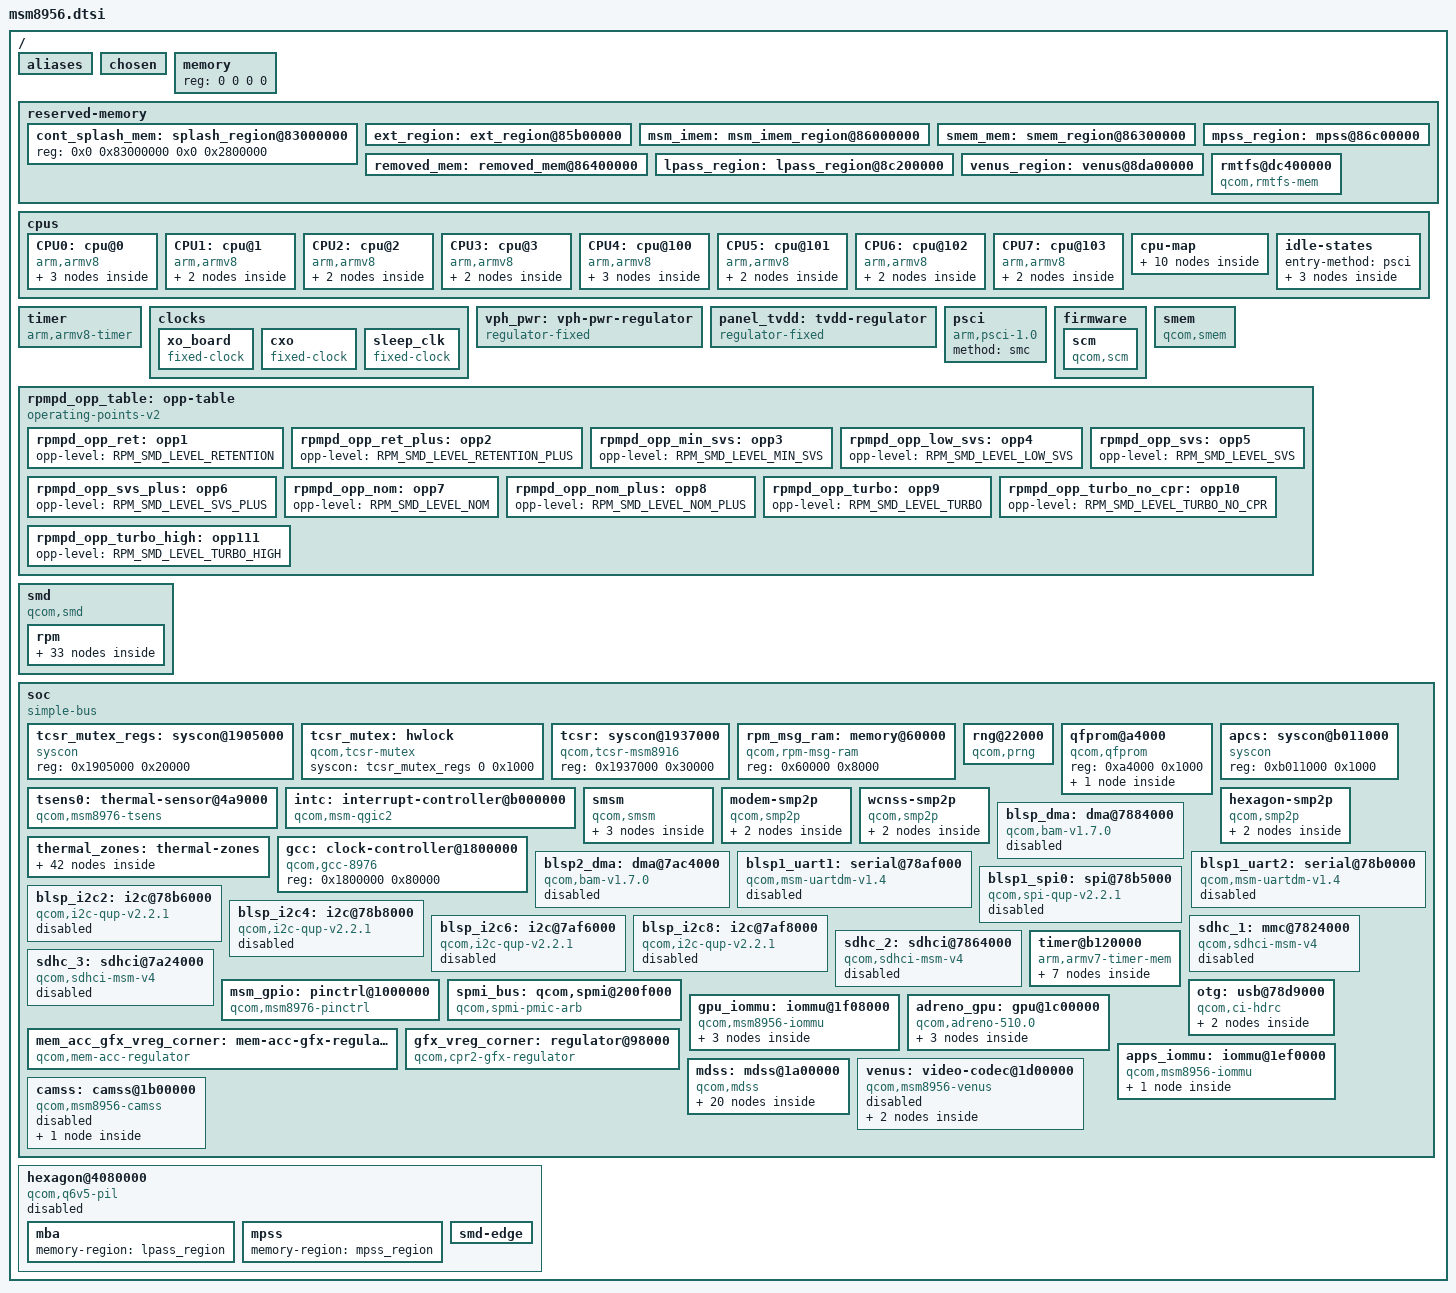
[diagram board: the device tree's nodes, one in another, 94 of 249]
// SPDX-License-Identifier: GPL-2.0
/* Copyright (c) 2014-2015, The Linux Foundation. All rights reserved.
 * Copyright (c) 2016-2019 AngeloGioacchino Del Regno <kholk11@gmail.com>
 */

#include <dt-bindings/interrupt-controller/arm-gic.h>
#include <dt-bindings/clock/qcom,gcc-msm8976.h>
#include <dt-bindings/clock/qcom,rpmcc.h>
#include <dt-bindings/power/qcom-rpmpd.h>

/ {
	interrupt-parent = <&intc>;

	qcom,msm-id = <266 0x10001>;

	#address-cells = <2>;
	#size-cells = <2>;

	aliases {
		sdhc1 = &sdhc_1; /* SDC1 eMMC slot */
		sdhc2 = &sdhc_2; /* SDC2 SD card slot */
		sdhc3 = &sdhc_3; /* SDC3 SDIO card slot */
		i2c2  = &blsp_i2c2;
		i2c4  = &blsp_i2c4;
		i2c6  = &blsp_i2c6;
		i2c8  = &blsp_i2c8;
		spi0  = &blsp1_spi0;
	};

	chosen { };

	memory {
		device_type = "memory";
		/* We expect the bootloader to fill in the reg */
		reg = <0 0 0 0>;
	};

	reserved-memory {
		#address-cells = <2>;
		#size-cells = <2>;
		ranges;

		cont_splash_mem: splash_region@83000000 {
			reg = <0x0 0x83000000 0x0 0x2800000>;
		};

		ext_region: ext_region@85b00000 {
			reg = <0x0 0x85b00000 0x0 0x500000>;
			no-map;
		};

		msm_imem: msm_imem_region@86000000 {
			reg = <0x0 0x86000000 0x0 0x300000>;
			no-map;
		};

		smem_mem: smem_region@86300000 {
			reg = <0x0 0x86300000 0x0 0x100000>;
			no-map;
		};

		removed_mem: removed_mem@86400000 {
			reg = <0x0 0x86400000 0x0 0x800000>;
			no-map;
		};

		mpss_region: mpss@86c00000 {
			reg = <0x0 0x86c00000 0x0 0x5600000>;
			no-map;
		};

		lpass_region: lpass_region@8c200000 {
			reg = <0x0 0x8c200000 0x0 0x1800000>;
			no-map;
		};

		venus_region: venus@8da00000 {
			reg = <0x0 0x8DA00000 0x0 0x2600000>;
			no-map;
		};
/*
		tz_apps: tz_apps@8dd00000 {
			reg = <0x0 0x8dd00000 0x0 0x1400000>;
			no-map;
		};
*/
		rmtfs@dc400000 {
			compatible = "qcom,rmtfs-mem";

			size = <0x0 0x200000>;
			alloc-ranges = <0x0 0xdc400000 0x0 0x2000000>;
			no-map;

			qcom,client-id = <1>;
		};
	};

	cpus {
		#address-cells = <1>;
		#size-cells = <0>;

		CPU0: cpu@0 {
			device_type = "cpu";
			compatible = "arm,armv8";
			reg = <0x0>;
			enable-method = "psci";
			cpu-idle-states = <&LITTLE_CPU_SLEEP_0>;
			capacity-dmips-mhz = <1024>;
			next-level-cache = <&L2_0>;
			#cooling-cells = <2>;
			L2_0: l2-cache {
				compatible = "arm,arch-cache";
				cache-level = <2>;
			};
			L1_I_0: l1-icache {
				compatible = "arm,arch-cache";
			};
			L1_D_0: l1-dcache {
				compatible = "arm,arch-cache";
			};
		};

		CPU1: cpu@1 {
			device_type = "cpu";
			compatible = "arm,armv8";
			reg = <0x1>;
			enable-method = "psci";
			cpu-idle-states = <&LITTLE_CPU_SLEEP_0>;
			capacity-dmips-mhz = <1024>;
			next-level-cache = <&L2_0>;
			#cooling-cells = <2>;
			L1_I_1: l1-icache {
				compatible = "arm,arch-cache";
			};
			L1_D_1: l1-dcache {
				compatible = "arm,arch-cache";
			};
		};

		CPU2: cpu@2 {
			device_type = "cpu";
			compatible = "arm,armv8";
			reg = <0x2>;
			enable-method = "psci";
			cpu-idle-states = <&LITTLE_CPU_SLEEP_0>;
			capacity-dmips-mhz = <1024>;
			next-level-cache = <&L2_0>;
			#cooling-cells = <2>;
			L1_I_2: l1-icache {
				compatible = "arm,arch-cache";
			};
			L1_D_2: l1-dcache {
				compatible = "arm,arch-cache";
			};
		};

		CPU3: cpu@3 {
			device_type = "cpu";
			compatible = "arm,armv8";
			reg = <0x3>;
			enable-method = "psci";
			cpu-idle-states = <&LITTLE_CPU_SLEEP_0>;
			capacity-dmips-mhz = <1024>;
			next-level-cache = <&L2_0>;
			#cooling-cells = <2>;
			L1_I_3: l1-icache {
				compatible = "arm,arch-cache";
			};
			L1_D_3: l1-dcache {
				compatible = "arm,arch-cache";
			};
		};

		CPU4: cpu@100 {
			device_type = "cpu";
			compatible = "arm,armv8";
			reg = <0x100>;
			enable-method = "psci";
			cpu-idle-states = <&BIG_CPU_SLEEP_0 &BIG_CPU_SLEEP_1>;
			capacity-dmips-mhz = <1830>;
			next-level-cache = <&L2_1>;
			#cooling-cells = <2>;
			L2_1: l2-cache {
				compatible = "arm,arch-cache";
				cache-level = <2>;
			};
			L1_I_100: l1-icache {
				compatible = "arm,arch-cache";
			};
			L1_D_100: l1-dcache {
				compatible = "arm,arch-cache";
			};
		};

		CPU5: cpu@101 {
			device_type = "cpu";
			compatible = "arm,armv8";
			reg = <0x101>;
			enable-method = "psci";
			cpu-idle-states = <&BIG_CPU_SLEEP_0 &BIG_CPU_SLEEP_1>;
			capacity-dmips-mhz = <1830>;
			next-level-cache = <&L2_1>;
			#cooling-cells = <2>;
			L1_I_101: l1-icache {
				compatible = "arm,arch-cache";
			};
			L1_D_101: l1-dcache {
				compatible = "arm,arch-cache";
			};
		};

		CPU6: cpu@102 {
			device_type = "cpu";
			compatible = "arm,armv8";
			reg = <0x102>;
			enable-method = "psci";
			cpu-idle-states = <&BIG_CPU_SLEEP_0 &BIG_CPU_SLEEP_1>;
			capacity-dmips-mhz = <1830>;
			next-level-cache = <&L2_1>;
			#cooling-cells = <2>;
			L1_I_102: l1-icache {
				compatible = "arm,arch-cache";
			};
			L1_D_102: l1-dcache {
				compatible = "arm,arch-cache";
			};
		};

		CPU7: cpu@103 {
			device_type = "cpu";
			compatible = "arm,armv8";
			reg = <0x103>;
			enable-method = "psci";
			cpu-idle-states = <&BIG_CPU_SLEEP_0 &BIG_CPU_SLEEP_1>;
			capacity-dmips-mhz = <1830>;
			next-level-cache = <&L2_1>;
			#cooling-cells = <2>;
			L1_I_103: l1-icache {
				compatible = "arm,arch-cache";
			};
			L1_D_103: l1-dcache {
				compatible = "arm,arch-cache";
			};
		};

		cpu-map {
			cluster0 {
				core0 {
					cpu = <&CPU0>;
				};

				core1 {
					cpu = <&CPU1>;
				};

				core2 {
					cpu = <&CPU2>;
				};

				core3 {
					cpu = <&CPU3>;
				};
			};

			cluster1 {
				core0 {
					cpu = <&CPU4>;
				};

				core1 {
					cpu = <&CPU5>;
				};

				core2 {
					cpu = <&CPU6>;
				};

				core3 {
					cpu = <&CPU7>;
				};
			};
		};

		idle-states {
			entry-method = "psci";

			LITTLE_CPU_SLEEP_0: cpu-sleep-0-0 {
				compatible = "arm,idle-state";
				idle-state-name = "little-power-collapse";
				arm,psci-suspend-param = <0x40000003>;
				entry-latency-us = <181>;
				exit-latency-us = <149>;
				min-residency-us = <703>;
				local-timer-stop;
			};

			BIG_CPU_SLEEP_0: cpu-sleep-1-0 {
				compatible = "arm,idle-state";
				idle-state-name = "big-retention";
				arm,psci-suspend-param = <0x00000002>;
				entry-latency-us = <142>;
				exit-latency-us = <99>;
				min-residency-us = <242>;
			};

			BIG_CPU_SLEEP_1: cpu-sleep-1-1 {
				compatible = "arm,idle-state";
				idle-state-name = "big-power-collapse";
				arm,psci-suspend-param = <0x40000003>;
				entry-latency-us = <158>;
				exit-latency-us = <144>;
				min-residency-us = <863>;
				local-timer-stop;
			};
		};
	};

	timer {
		compatible = "arm,armv8-timer";
		interrupts = <GIC_PPI 2 (GIC_CPU_MASK_SIMPLE(1) | IRQ_TYPE_LEVEL_LOW)>,
			     <GIC_PPI 3 (GIC_CPU_MASK_SIMPLE(1) | IRQ_TYPE_LEVEL_LOW)>,
			     <GIC_PPI 4 (GIC_CPU_MASK_SIMPLE(1) | IRQ_TYPE_LEVEL_LOW)>,
			     <GIC_PPI 1 (GIC_CPU_MASK_SIMPLE(1) | IRQ_TYPE_LEVEL_LOW)>;
		clock-frequency = <19200000>;
	};

	clocks {
		xo_board: xo_board {
			compatible = "fixed-clock";
			#clock-cells = <0>;
			clock-frequency = <19200000>;
			clock-output-names = "xo_board";
		};

		cxo: cxo {
			compatible = "fixed-clock";
			#clock-cells = <0>;
			clock-frequency = <19200000>;
			clock-output-names = "cxo";
		};

		sleep_clk: sleep_clk {
			compatible = "fixed-clock";
			#clock-cells = <0>;
			clock-frequency = <32764>;
			clock-output-names = "sleep_clk";
		};
	};

	vph_pwr: vph-pwr-regulator {
		compatible = "regulator-fixed";
		regulator-name = "vph_pwr";
		regulator-always-on;
		regulator-boot-on;
	};

	panel_tvdd: tvdd-regulator {
		compatible = "regulator-fixed";
		regulator-name = "panel-tvdd";
		gpio = <&msm_gpio 126 0>;
		// This regulator is active-low.
	};

	psci {
		compatible = "arm,psci-1.0";
		method = "smc";
	};

	firmware {
		scm: scm {
			compatible = "qcom,scm";
			clocks = <&gcc GCC_CRYPTO_CLK>,
				 <&gcc GCC_CRYPTO_AXI_CLK>,
				 <&gcc GCC_CRYPTO_AHB_CLK>;
			clock-names = "core", "bus", "iface";
			#reset-cells = <1>;

			qcom,dload-mode = <&tcsr 0x6100>;
		};
	};

	smem {
		compatible = "qcom,smem";

		memory-region = <&smem_mem>;
		qcom,rpm-msg-ram = <&rpm_msg_ram>;

		hwlocks = <&tcsr_mutex 3>;
	};

	rpmpd_opp_table: opp-table {
		compatible = "operating-points-v2";

		rpmpd_opp_ret: opp1 {
			opp-level = <RPM_SMD_LEVEL_RETENTION>;
		};

		rpmpd_opp_ret_plus: opp2 {
			opp-level = <RPM_SMD_LEVEL_RETENTION_PLUS>;
		};

		rpmpd_opp_min_svs: opp3 {
			opp-level = <RPM_SMD_LEVEL_MIN_SVS>;
		};

		rpmpd_opp_low_svs: opp4 {
			opp-level = <RPM_SMD_LEVEL_LOW_SVS>;
		};

		rpmpd_opp_svs: opp5 {
			opp-level = <RPM_SMD_LEVEL_SVS>;
		};

		rpmpd_opp_svs_plus: opp6 {
			opp-level = <RPM_SMD_LEVEL_SVS_PLUS>;
		};

		rpmpd_opp_nom: opp7 {
			opp-level = <RPM_SMD_LEVEL_NOM>;
		};

		rpmpd_opp_nom_plus: opp8 {
			opp-level = <RPM_SMD_LEVEL_NOM_PLUS>;
		};

		rpmpd_opp_turbo: opp9 {
			opp-level = <RPM_SMD_LEVEL_TURBO>;
		};

		rpmpd_opp_turbo_no_cpr: opp10 {
			opp-level = <RPM_SMD_LEVEL_TURBO_NO_CPR>;
		};

		rpmpd_opp_turbo_high: opp111 {
			opp-level = <RPM_SMD_LEVEL_TURBO_HIGH>;
		};
	};

	smd {
		compatible = "qcom,smd";

		rpm {
			interrupts = <GIC_SPI 168 IRQ_TYPE_EDGE_RISING>;
			qcom,ipc = <&apcs 8 0>;
			qcom,smd-edge = <15>;

			rpm_requests {
				compatible = "qcom,rpm-msm8976";
				qcom,smd-channels = "rpm_requests";

				rpmcc: qcom,rpmcc {
					compatible = "qcom,rpmcc-msm8976";
					#clock-cells = <1>;
				};

				rpmpd: power-controller {
					compatible = "qcom,msm8956-rpmpd";
					#power-domain-cells = <1>;
					operating-points-v2 = <&rpmpd_opp_table>;
				};

				smd_rpm_regulators: pm8956-regulators {
					compatible = "qcom,rpm-pm8950-regulators";

					pm8950_s1: s1 {};
					pm8950_s2: s2 {};
					pm8950_s3: s3 {};
					pm8950_s4: s4 {};
					pm8950_s5: s5 {};
					pm8950_s6: s6 {};

					pm8950_l1: l1 {};
					pm8950_l2: l2 {};
					pm8950_l3: l3 {};
					pm8950_l4: l4 {};
					pm8950_l5: l5 {};
					pm8950_l6: l6 {};
					pm8950_l7: l7 {};
					pm8950_l8: l8 {};
					pm8950_l9: l9 {};
					pm8950_l10: l10 {};
					pm8950_l11: l11 {};
					pm8950_l12: l12 {};
					pm8950_l13: l13 {};
					pm8950_l14: l14 {};
					pm8950_l15: l15 {};
					pm8950_l16: l16 {};
					pm8950_l17: l17 {};
					pm8950_l18: l18 {};
					pm8950_l19: l19 {};
					pm8950_l20: l20 {};
					pm8950_l21: l21 {};
					pm8950_l22: l22 {};
					pm8950_l23: l23 {};
				};
			};
		};
	};

	soc: soc {
		#address-cells = <1>;
		#size-cells = <1>;
		ranges = <0 0 0 0xffffffff>;
		compatible = "simple-bus";

		tcsr_mutex_regs: syscon@1905000 {
			compatible = "syscon";
			reg = <0x1905000 0x20000>;
		};

		tcsr_mutex: hwlock {
			compatible = "qcom,tcsr-mutex";
			syscon = <&tcsr_mutex_regs 0 0x1000>;
			#hwlock-cells = <1>;
		};

		tcsr: syscon@1937000 {
			compatible = "qcom,tcsr-msm8916", "syscon";
			reg = <0x1937000 0x30000>;
		};

		rpm_msg_ram: memory@60000 {
			compatible = "qcom,rpm-msg-ram";
			reg = <0x60000 0x8000>;
		};

		rng@22000 {
			compatible = "qcom,prng";
			reg = <0x22000 0x140>;
			clocks = <&gcc GCC_PRNG_AHB_CLK>;
			clock-names = "core";
		};

		qfprom@a4000 {
			compatible = "qcom,qfprom";
			reg = <0xa4000 0x1000>;
			#address-cells = <1>;
			#size-cells = <1>;

			tsens_caldata: caldata@218 {
				reg = <0x218 0x18>;
			};
		};

		tsens0: thermal-sensor@4a9000 {
			compatible = "qcom,msm8976-tsens";
			reg = <0x4a9000 0x1000>, /* TM */
			      <0x4a8000 0x1000>; /* SROT */
			nvmem-cells = <&tsens_caldata>;
			nvmem-cell-names = "calib";
			#qcom,sensors = <11>;
			#thermal-sensor-cells = <1>;
		};

		intc: interrupt-controller@b000000 {
			compatible = "qcom,msm-qgic2";
			interrupt-controller;
			#interrupt-cells = <3>;
			reg = <0x0b000000 0x1000>,
			      <0x0b002000 0x1000>;
		};

		/* TODO: PLLs! A53PLL: 0xb016000 HFPLL: 0xb116000 */

		apcs: syscon@b011000 {
			compatible = "syscon";
			reg = <0xb011000 0x1000>;
		};

		smsm {
			compatible = "qcom,smsm";

			#address-cells = <1>;
			#size-cells = <0>;

			qcom,ipc-1 = <&apcs 8 12>;
			qcom,ipc-2 = <&apcs 8 9>;
			qcom,ipc-3 = <&apcs 8 18>;

			apps_smsm: apps@0 {
				reg = <0>;
				#qcom,smem-state-cells = <1>;
			};

			hexagon_smsm: hexagon@1 {
				reg = <1>;
				interrupts = <0 290 IRQ_TYPE_EDGE_RISING>;

				interrupt-controller;
				#interrupt-cells = <2>;
			};

			wcnss_smsm: wcnss@6 {
				reg = <6>;
				interrupts = <GIC_SPI 144 IRQ_TYPE_EDGE_RISING>;

				interrupt-controller;
				#interrupt-cells = <2>;
			};
		};

		modem-smp2p {
			compatible = "qcom,smp2p";
			qcom,smem = <435>, <428>;

			interrupts = <GIC_SPI 27 IRQ_TYPE_EDGE_RISING>;

			qcom,ipc = <&apcs 8 13>;

			qcom,local-pid = <0>;
			qcom,remote-pid = <1>;

			modem_smp2p_out: master-kernel {
				qcom,entry-name = "master-kernel";

				#qcom,smem-state-cells = <1>;
			};

			modem_smp2p_in: slave-kernel {
				qcom,entry-name = "slave-kernel";

				interrupt-controller;
				#interrupt-cells = <2>;
			};
		};

		wcnss-smp2p {
			compatible = "qcom,smp2p";
			qcom,smem = <451>, <431>;

			interrupts = <GIC_SPI 143 IRQ_TYPE_EDGE_RISING>;

			qcom,ipc = <&apcs 8 17>;

			qcom,local-pid = <0>;
			qcom,remote-pid = <4>;

			wcnss_smp2p_out: master-kernel {
				qcom,entry-name = "master-kernel";

				#qcom,smem-state-cells = <1>;
			};

			wcnss_smp2p_in: slave-kernel {
				qcom,entry-name = "slave-kernel";

				interrupt-controller;
				#interrupt-cells = <2>;
			};
		};

		hexagon-smp2p {
			compatible = "qcom,smp2p";
			qcom,smem = <443>, <429>;

			interrupts = <GIC_SPI 291 IRQ_TYPE_EDGE_RISING>;

			qcom,ipc = <&apcs 8 10>;

			qcom,local-pid = <0>;
			qcom,remote-pid = <2>;

			adsp_smp2p_out: master-kernel {
				qcom,entry-name = "master-kernel";

				#qcom,smem-state-cells = <1>;
			};

			adsp_smp2p_in: slave-kernel {
				qcom,entry-name = "slave-kernel";

				interrupt-controller;
				#interrupt-cells = <2>;
			};
		};

		thermal_zones: thermal-zones {};

		gcc: clock-controller@1800000 {
			compatible = "qcom,gcc-8976";
			#clock-cells = <1>;
			#reset-cells = <1>;
			#power-domain-cells = <1>;
			reg = <0x1800000 0x80000>;
		};

		blsp_dma: dma@7884000 {
			compatible = "qcom,bam-v1.7.0";
			reg = <0x07884000 0x1f000>;
			interrupts = <GIC_SPI 238 IRQ_TYPE_LEVEL_HIGH>;
			clocks = <&gcc GCC_BLSP1_AHB_CLK>;
			clock-names = "bam_clk";
			#dma-cells = <1>;
			qcom,ee = <0>;
			status = "disabled";
		};

		blsp2_dma: dma@7ac4000 {
			compatible = "qcom,bam-v1.7.0";
			reg = <0x7ac4000 0x1f000>;
			interrupts = <GIC_SPI 239 IRQ_TYPE_LEVEL_HIGH>;
			clocks = <&gcc GCC_BLSP2_AHB_CLK>;
			clock-names = "bam_clk";
			#dma-cells = <1>;
			qcom,ee = <0>;
			status = "disabled";
		};

		blsp1_uart1: serial@78af000 {
			compatible = "qcom,msm-uartdm-v1.4", "qcom,msm-uartdm";
			reg = <0x78af000 0x200>;
			interrupts = <GIC_SPI 107 IRQ_TYPE_LEVEL_HIGH>;
			clocks = <&gcc GCC_BLSP1_UART1_APPS_CLK>, <&gcc GCC_BLSP1_AHB_CLK>;
			clock-names = "core", "iface";
			dmas = <&blsp_dma 1>, <&blsp_dma 0>;
			dma-names = "rx", "tx";
			status = "disabled";
		};

		blsp1_uart2: serial@78b0000 {
			compatible = "qcom,msm-uartdm-v1.4", "qcom,msm-uartdm";
			reg = <0x78b0000 0x200>;
			interrupts = <GIC_SPI 108 IRQ_TYPE_LEVEL_HIGH>;
			clocks = <&gcc GCC_BLSP1_UART2_APPS_CLK>, <&gcc GCC_BLSP1_AHB_CLK>;
			clock-names = "core", "iface";
			dmas = <&blsp_dma 3>, <&blsp_dma 2>;
			dma-names = "rx", "tx";
			status = "disabled";
		};


		blsp1_spi0: spi@78b5000 {
			compatible = "qcom,spi-qup-v2.2.1";
			reg = <0x078b5000 0x500>;
			interrupts = <GIC_SPI 95 IRQ_TYPE_LEVEL_HIGH>;
			clocks = <&gcc GCC_BLSP1_QUP1_SPI_APPS_CLK>,
				 <&gcc GCC_BLSP1_AHB_CLK>;
			clock-names = "core", "iface";
			dmas = <&blsp_dma 5>, <&blsp_dma 4>;
			dma-names = "rx", "tx";
			pinctrl-names = "default", "sleep";
			pinctrl-0 = <&spi0_default>;
			pinctrl-1 = <&spi0_sleep>;
			#address-cells = <1>;
			#size-cells = <0>;
			status = "disabled";
		};

		blsp_i2c2: i2c@78b6000 {
			compatible = "qcom,i2c-qup-v2.2.1";
			reg = <0x078b6000 0x500>;
			interrupts = <GIC_SPI 96 IRQ_TYPE_LEVEL_HIGH>;
			clocks = <&gcc GCC_BLSP1_AHB_CLK>,
				 <&gcc GCC_BLSP1_QUP2_I2C_APPS_CLK>;
			clock-names = "iface", "core";
			pinctrl-names = "default", "sleep";
			pinctrl-0 = <&i2c2_default>;
			pinctrl-1 = <&i2c2_sleep>;
			#address-cells = <1>;
			#size-cells = <0>;
			status = "disabled";
		};

		blsp_i2c4: i2c@78b8000 {
			compatible = "qcom,i2c-qup-v2.2.1";
			reg = <0x078b8000 0x500>;
			interrupts = <GIC_SPI 98 IRQ_TYPE_LEVEL_HIGH>;
			clocks = <&gcc GCC_BLSP1_AHB_CLK>,
				 <&gcc GCC_BLSP1_QUP4_I2C_APPS_CLK>;
			clock-names = "iface", "core";
			pinctrl-names = "default", "sleep";
			pinctrl-0 = <&i2c4_default>;
			pinctrl-1 = <&i2c4_sleep>;
			#address-cells = <1>;
			#size-cells = <0>;
			status = "disabled";
		};

		blsp_i2c6: i2c@7af6000 {
			compatible = "qcom,i2c-qup-v2.2.1";
			reg = <0x7af6000 0x600>;
			interrupts = <GIC_SPI 300 IRQ_TYPE_LEVEL_HIGH>;
			clocks = <&gcc GCC_BLSP2_AHB_CLK>,
				 <&gcc GCC_BLSP2_QUP2_I2C_APPS_CLK>;
			clock-names = "iface", "core";
			pinctrl-names = "default", "sleep";
			pinctrl-0 = <&i2c6_default>;
			pinctrl-1 = <&i2c6_sleep>;
			#address-cells = <1>;
			#size-cells = <0>;
			status = "disabled";
		};

		blsp_i2c8: i2c@7af8000 {
			compatible = "qcom,i2c-qup-v2.2.1";
			reg = <0x7af8000 0x600>;
			interrupts = <GIC_SPI 302 IRQ_TYPE_LEVEL_HIGH>;
			clocks = <&gcc GCC_BLSP2_AHB_CLK>,
				 <&gcc GCC_BLSP2_QUP4_I2C_APPS_CLK>;
			clock-names = "iface", "core";
			pinctrl-names = "default", "sleep";
			pinctrl-0 = <&i2c8_default>;
			pinctrl-1 = <&i2c8_sleep>;
			#address-cells = <1>;
			#size-cells = <0>;
			status = "disabled";
		};

		sdhc_1: mmc@7824000 {
			compatible = "qcom,sdhci-msm-v4";
			reg = <0x07824900 0x500>, <0x07824000 0x800>;
			reg-names = "hc_mem", "core_mem";

			interrupts = <GIC_SPI 123 IRQ_TYPE_LEVEL_HIGH>,
				     <GIC_SPI 138 IRQ_TYPE_LEVEL_HIGH>;
			interrupt-names = "hc_irq", "pwr_irq";

			clocks = <&gcc GCC_SDCC1_APPS_CLK>,
				 <&gcc GCC_SDCC1_AHB_CLK>,
				 <&xo_board>;
			clock-names = "core", "iface", "xo";

			mmc-hs400-1_8v;
			bus-width = <8>;
			non-removable;
			status = "disabled";
		};

		sdhc_2: sdhci@7864000 {
			compatible = "qcom,sdhci-msm-v4";
			reg = <0x07864900 0x11c>, <0x07864000 0x800>;
			reg-names = "hc_mem", "core_mem";

			interrupts = <GIC_SPI 125 IRQ_TYPE_LEVEL_HIGH>,
				     <GIC_SPI 221 IRQ_TYPE_LEVEL_HIGH>;
			interrupt-names = "hc_irq", "pwr_irq";

			clocks = <&gcc GCC_SDCC2_APPS_CLK>,
				 <&gcc GCC_SDCC2_AHB_CLK>,
				 <&xo_board>;
			clock-names = "core", "iface", "xo";

			bus-width = <4>;
			status = "disabled";
		};

		sdhc_3: sdhci@7a24000 {
			compatible = "qcom,sdhci-msm-v4";
			reg = <0x7a24900 0x11c>, <0x7a24000 0x800>;
			reg-names = "hc_mem", "core_mem";

			interrupts = <GIC_SPI 295 IRQ_TYPE_LEVEL_HIGH>,
				     <GIC_SPI 297 IRQ_TYPE_LEVEL_HIGH>;
			interrupt-names = "hc_irq", "pwr_irq";

			clocks = <&gcc GCC_SDCC3_APPS_CLK>,
				 <&gcc GCC_SDCC3_AHB_CLK>,
				 <&xo_board>;
			clock-names = "core", "iface", "xo";

			bus-width = <4>;
			status = "disabled";
		};


		msm_gpio: pinctrl@1000000 {
			compatible = "qcom,msm8976-pinctrl";
			reg = <0x1000000 0x300000>;
			interrupts = <GIC_SPI 208 IRQ_TYPE_LEVEL_HIGH>;
			gpio-controller;
			#gpio-cells = <2>;
			interrupt-controller;
			#interrupt-cells = <2>;
		};

		timer@b120000 {
			#address-cells = <1>;
			#size-cells = <1>;
			ranges;
			compatible = "arm,armv7-timer-mem";
			reg = <0xb120000 0x1000>;
			clock-frequency = <19200000>;

			frame@b121000 {
				frame-number = <0>;
				interrupts = <GIC_SPI 8 IRQ_TYPE_LEVEL_HIGH>,
					     <GIC_SPI 7 IRQ_TYPE_LEVEL_HIGH>;
				reg = <0xb121000 0x1000>,
				      <0xb122000 0x1000>;
			};

			frame@b123000 {
				frame-number = <1>;
				interrupts = <GIC_SPI 9 IRQ_TYPE_LEVEL_HIGH>;
				reg = <0xb123000 0x1000>;
				status = "disabled";
			};

			frame@b124000 {
				frame-number = <2>;
				interrupts = <GIC_SPI 10 IRQ_TYPE_LEVEL_HIGH>;
				reg = <0xb124000 0x1000>;
				status = "disabled";
			};

			frame@b125000 {
				frame-number = <3>;
				interrupts = <GIC_SPI 11 IRQ_TYPE_LEVEL_HIGH>;
				reg = <0xb125000 0x1000>;
				status = "disabled";
			};

			frame@b126000 {
				frame-number = <4>;
				interrupts = <GIC_SPI 12 IRQ_TYPE_LEVEL_HIGH>;
				reg = <0xb126000 0x1000>;
				status = "disabled";
			};

			frame@b127000 {
				frame-number = <5>;
				interrupts = <GIC_SPI 13 IRQ_TYPE_LEVEL_HIGH>;
				reg = <0xb127000 0x1000>;
				status = "disabled";
			};

			frame@b128000 {
				frame-number = <6>;
				interrupts = <GIC_SPI 14 IRQ_TYPE_LEVEL_HIGH>;
				reg = <0xb128000 0x1000>;
				status = "disabled";
			};
		};

		spmi_bus: qcom,spmi@200f000 {
			compatible = "qcom,spmi-pmic-arb";
			reg = <0x200f000 0x1000>,
				<0x2400000 0x800000>,
				<0x2c00000 0x800000>,
				<0x3800000 0x200000>,
				<0x200a000 0x2100>;
			reg-names = "core", "chnls", "obsrvr", "intr", "cnfg";
			interrupts = <GIC_SPI 190 IRQ_TYPE_LEVEL_HIGH>;
			interrupt-names = "periph_irq";
			qcom,channel = <0>;
			qcom,ee = <0>;

			#address-cells = <2>;
			#size-cells = <0>;
			interrupt-controller;
			#interrupt-cells = <4>;
			cell-index = <0>;
		};

		otg: usb@78d9000 {
			compatible = "qcom,ci-hdrc";
			reg = <0x78db000 0x200>,
			      <0x78db200 0x200>;
			interrupts = <GIC_SPI 134 IRQ_TYPE_LEVEL_HIGH>,
				     <GIC_SPI 140 IRQ_TYPE_LEVEL_HIGH>;
			clocks = <&gcc GCC_USB_HS_AHB_CLK>,
				 <&gcc GCC_USB_HS_SYSTEM_CLK>;
			clock-names = "iface", "core";
			assigned-clocks = <&gcc GCC_USB_HS_SYSTEM_CLK>;
			assigned-clock-rates = <80000000>;
			resets = <&gcc RST_USB_HS_BCR>;
			reset-names = "core";
			phy_type = "ulpi";
			dr_mode = "peripheral";
			ahb-burst-config = <0>;
			phy-names = "usb-phy";
			phys = <&usb_hs_phy>;
			status = "ok";
			#reset-cells = <1>;

			extcon = <&usb_vbus>, <&usb_id>;

			ulpi {
				usb_hs_phy: phy@0x6c000 {
					#phy-cells = <0>;
					//vdd-supply = <&pm8950_s6>;
					vdda1p8-supply = <&pm8950_l7>;
					vdda3p3-supply = <&pm8950_l13>;
					qcom,vdd-voltage-level = <0 256 512>;/* <RPM_SMD_REGULATOR_LEVEL_NONE
								RPM_SMD_REGULATOR_LEVEL_NOM
								RPM_SMD_REGULATOR_LEVEL_BINNING>;*/
					clocks = <&xo_board>,
						<&gcc GCC_USB_HS_PHY_CFG_AHB_CLK>,
						<&gcc GCC_USB2A_PHY_SLEEP_CLK>;
					clock-names = "ref", "phy", "sleep";
					resets = <&gcc RST_QUSB2_PHY_BCR>,
						<&gcc RST_USB2_HS_PHY_ONLY_BCR>;
					reset-names = "phy", "por";

					extcon = <&usb_vbus>;
					// port {
					// 	ep_usb_phy: endpoint {
					// 		remote-endpoint = <&usb_vbus>;
					// 	};
					// };
				};
			};
		};

#define USE_UPSTREAM_MMU 1
#if USE_UPSTREAM_MMU
		gpu_iommu: iommu@1f08000 {
			#address-cells = <1>;
			#size-cells = <1>;
			#iommu-cells = <1>;
			compatible = "qcom,msm8956-iommu", "qcom,msm-iommu-v1";
			ranges = <0 0x1f08000 0x8000>;
			clocks = <&gcc GCC_SMMU_CFG_CLK>,
				 <&gcc GCC_GFX3D_TCU_CLK>;
			clock-names = "iface", "bus";
			qcom,iommu-secure-id = <18>;

			// gfx3d_user:
			iommu-ctx@0 {
				compatible = "qcom,msm-iommu-v1-ns";
				reg = <0x0 0x1000>;
				qcom,ctx-num = <0>;
				interrupts = <GIC_SPI 240 IRQ_TYPE_LEVEL_HIGH>;
			};

			// gfx3d_sec:
			iommu-ctx@2000 {
				compatible = "qcom,msm-iommu-v2-sec";
				reg = <0x1000 0x1000>;
				qcom,ctx-num = <2>;
				interrupts = <GIC_SPI 241 IRQ_TYPE_LEVEL_HIGH>;
			};

			// gfx3d_priv:
			iommu-ctx@3000 {
				compatible = "qcom,msm-iommu-v2-sec";
				reg = <0x2000 0x1000>;
				qcom,ctx-num = <1>;
				interrupts = <GIC_SPI 242 IRQ_TYPE_LEVEL_HIGH>;
			};

		};
#else
		/*
		 * kgsl_smmu range: 0x1f00000 - 0x1f10000
		 *
		 *  === context mapping ===
		 * 0x1f00000 - 0x1f08000: General purpose KGSL range
		 * 0x1f08000 - 0x1f09000: User (not secure) context
		 * 0x1f09000 - 0x1f0a000: Secure KGSL context
		 * 0x1f0a000 - 0x1f0b000: Private KGSL context (deprecated)
		 * 0x1f0b000 - 0x1f10000: Unused range?
		 *
		 *  === config irqs ===
		 * global_cfg_S_irq:  <0 42 0>
		 * global_cfg_NS_irq: <0 43 0>
		 *
		 *  === other irqs ===
		 * User context:    240
		 * Secure context:  241
		 * Private context: 242
		 */

		gpu_iommu: iommu@1f00000 {
			compatible = "qcom,msm-smmu-v2", "qcom,msm-mmu-500";
			#address-cells = <1>;
			#size-cells = <1>;
			#iommu-cells = <1>;
			//ranges = <0 0x1f00000 0x10000>;
			//dma-ranges;
			reg = <0x1f00000 0x10000>;
			reg-names = "iommu_base";
			interrupts = <GIC_SPI 43 IRQ_TYPE_LEVEL_HIGH>,
				     <GIC_SPI 42 IRQ_TYPE_LEVEL_HIGH>;
			interrupt-names = "global_cfg_NS_irq", "global_cfg_S_irq";
			label = "gfx_iommu";
			qcom,qcom,use-aarch64-addressing;
			qcom,iommu-secure-id = <18>;
			clocks = <&gcc GCC_SMMU_CFG_CLK>,
				 <&gcc GCC_GFX3D_TCU_CLK>;
			clock-names = "iface_clk", "core_clk";
			status = "ok";

/* s6_level_ao, s2_level_ao ... wrong.....
			power-domains = <&rpmpd MSM8956_VDDCX_VLVL>, <&rpmpd MSM8956_VDDMX_VLVL>;
			power-domain-names = "cx", "mx";
*/
			iommu-ctx@1f08000 {
				compatible = "qcom,msm-smmu-v2-ctx";
				reg = <0x1f08000 0x1000>;
				interrupts = <GIC_SPI 240 IRQ_TYPE_LEVEL_HIGH>;
				qcom,ctx-num = <0>;
				label = "gfx3d_user";
			};

			iommu-ctx@1f09000 {
				compatible = "qcom,msm-smmu-v2-ctx";
				reg = <0x1f09000 0x1000>;
				qcom,secure-context;
				interrupts = <GIC_SPI 241 IRQ_TYPE_LEVEL_HIGH>;
				qcom,ctx-num = <2>;
				label = "gfx3d_secure";
			};

			iommu-ctx@1f0a000 {
				compatible = "qcom,msm-smmu-v2-ctx";
				reg = <0x1f0a000 0x1000>;
				qcom,secure-context;
				qcom,ctx-num = <1>;
				interrupts = <GIC_SPI 242 IRQ_TYPE_LEVEL_HIGH>;
				label = "gfx3d_priv";
			};
		};
#endif

/* @@@@@@@@@@@@@@@@@@@ HUGE UGLY HACK - START - @@@@@@@@@@@@@@@@@@@ */
	mem_acc_gfx_vreg_corner: mem-acc-gfx-regulator {
		compatible = "qcom,mem-acc-regulator";
		reg = <0x01944130 0x4>;
		reg-names = "acc-sel-l1";
		regulator-name = "mem_acc_gfx_corner";
		regulator-min-microvolt = <1>;
		regulator-max-microvolt = <9>;

		qcom,acc-sel-l1-bit-pos = <0>;
		qcom,acc-sel-l1-bit-size = <2>;
		qcom,corner-acc-map = <0 0 0 1 1 1 1 1 1>;
	};

	/* CPR regulators */
	gfx_vreg_corner: regulator@98000 {
		compatible = "qcom,cpr2-gfx-regulator";
		reg = <0x98000 0x1000>, <0xa4000 0x1000>;
		reg-names = "rbcpr", "efuse_addr";
		clocks = <&gcc GCC_RBCPR_GFX_CLK>,
			 <&gcc GCC_RBCPR_GFX_AHB_CLK>;
		clock-names = "core_clk", "iface_clk";
		interrupts = <GIC_SPI 314 IRQ_TYPE_LEVEL_HIGH>;

		regulator-name = "gfx_corner";
		qcom,cpr-corners = <9>;
		regulator-min-microvolt = <1>;
		regulator-max-microvolt = <9>;

		qcom,cpr-voltage-ceiling =
				<810000 865000 900000 950000 1010000
				1050000 1110000 1165000 1165000>;
		qcom,cpr-voltage-floor =
				<755000 755000 755000 795000 835000
				855000 920000 945000 945000>;

		mem-acc-supply = <&mem_acc_gfx_vreg_corner>;

		qcom,cpr-ref-clk = <19200>;
		qcom,cpr-timer-delay = <5000>;
		qcom,cpr-timer-cons-up = <0>;
		qcom,cpr-timer-cons-down = <2>;
		qcom,cpr-irq-line = <0>;
		qcom,cpr-step-quotient = <16>;
		qcom,cpr-up-threshold = <2>;
		qcom,cpr-down-threshold = <4>;
		qcom,cpr-idle-clocks = <15>;
		qcom,cpr-gcnt-time = <1>;
		qcom,vdd-gfx-step-up-limit = <1>;
		qcom,vdd-gfx-step-down-limit = <1>;
		qcom,cpr-gfx-volt-step = <5000>;

		qcom,cpr-init-voltage-ref =
				<865000 865000 950000 950000 950000
				1050000 1050000 1165000 1165000>;
		qcom,cpr-fuse-init-voltage =
					<72 50 5>,
					<72 50 5>,
					<72 45 5>,
					<72 45 5>,
					<72 45 5>,
					<72 40 5>,
					<72 40 5>,
					<72 35 5>,
					<72 35 5>;
		qcom,cpr-init-voltage-step = <12500>;
		qcom,cpr-ro-count = <8>;
		qcom,cpr-init-voltage-as-ceiling;
		qcom,cpr-init-voltage-adjustment =
			<(-55000) 0 (-60000) 0 (60000) 0 (60000) 0 (50000)>;
		qcom,cpr-target-quotients =
			<513  489  620  574  237 272 144 177>,
			<575  547  688  638  272 312 169 206>,
			<706  672  819  765  363 410 241 287>,
			<768  741  890  843  404 450 277 323>,
			<917  880  1039 982  514 562 369 421>,
			<998  960  1126 1069 571 617 422 472>,
			<1074 1028 1198 1135 635 675 483 531>,
			<1188 1135 1317 1246 720 753 562 605>,
			<1276 1212 1405 1323 776 816 604 654>;
		qcom,cpr-enable;
	};

/* @@@@@@@@@@@@@@@@@@@ HUGE UGLY HACK -  END  - @@@@@@@@@@@@@@@@@@@ */

		adreno_gpu: gpu@1c00000 {
			compatible = "qcom,adreno-510.0", "qcom,adreno";
			reg = <0x01c00000 0x40000>;
			reg-names = "kgsl_3d0_reg_memory";
			interrupts = <GIC_SPI 33 IRQ_TYPE_LEVEL_HIGH>;
			interrupt-names = "kgsl_3d0_irq";

			clock-names =
			    "core",
			    "iface",
			    "mem",
			    "rbbmtimer",
			    "gtcu",
			    "gtbu",
			    "alwayson";

			clocks =
			    <&gcc GCC_GFX3D_OXILI_CLK>,
			    <&gcc GCC_GFX3D_OXILI_AHB_CLK>,
			    <&gcc GCC_GFX3D_BIMC_CLK>,
			    <&gcc GCC_GFX3D_OXILI_TIMER_CLK>,
			    <&gcc GCC_GFX3D_GTCU_AHB_CLK>,
			    <&gcc GCC_GFX3D_TBU1_CLK>,
			    <&gcc GCC_GFX3D_OXILI_AON_CLK>;

			power-domains = <&gcc OXILI_CX_GDSC>;
			operating-points-v2 = <&gpu_opp_table>;
			iommus = <&gpu_iommu 0>;

			gpu_opp_table: opp_table {
				compatible = "operating-points-v2";

				opp-200000000 {
					opp-hz = /bits/ 64 <200000000>;
				};
				opp-160000000 {
					opp-hz = /bits/ 64 <160000000>;
				};
			};
		};
#if USE_UPSTREAM_MMU
		apps_iommu: iommu@1ef0000 {
			#address-cells = <1>;
			#size-cells = <1>;
			#iommu-cells = <1>;
			compatible = "qcom,msm8956-iommu", "qcom,msm-iommu-v1";
			ranges = <0 0x1e19000 0x40000>;
			clocks = <&gcc GCC_SMMU_CFG_CLK>,
				 <&gcc GCC_APSS_TCU_CLK>;
			clock-names = "iface", "bus";
			qcom,iommu-secure-id = <17>;
			status="ok";
/*
			// vfe:
			iommu-ctx@1c000 {
				compatible = "qcom,msm-iommu-v1-sec";
				reg = <0x1c000 0x1000>;
				qcom,ctx-asid = <20>;
				interrupts = <GIC_SPI 113 IRQ_TYPE_LEVEL_HIGH>;
			};

			// venus_ns:
			iommu-ctx@1d000 {
				compatible = "qcom,msm-iommu-v1-sec";
				reg = <0x1d000 0x1000>;
				qcom,ctx-asid = <21>;
				interrupts = <GIC_SPI 114 IRQ_TYPE_LEVEL_HIGH>;
			};
*/
			// mdp_0:
			iommu-ctx@1e000 {
				compatible = "qcom,msm-iommu-v1-ns";
				reg = <0x1e000 0x1000>;
				qcom,ctx-num = <22>;
				interrupts = <GIC_SPI 115 IRQ_TYPE_LEVEL_HIGH>;
			};
		};
#else

		/*
		 * apps_iommu range: 0x1e00000 - 0x1e40000
		 *
		 *  === context mapping ===
		 * 0x1e00000 - 0x1e20000: General purpose APPS range
		 * 0x1e20000 - 0x1e21000: ADSP ELF Secure context
		 * 0x1e21000 - 0x1e22000: ADSP secure pixel context
		 * 0x1e22000 - 0x1e23000: ADSP secure bit stream context
		 * 0x1e23000 - 0x1e24000: Venus firmware secure context
		 * 0x1e24000 - 0x1e25000: Venus non pixel secure context
		 * 0x1e25000 - 0x1e26000: Venus secure bit stream context
		 * 0x1e26000 - 0x1e27000: Venus secure pixel context
		 * 0x1e27000 - 0x1e28000: Venus encoder secure context
		 * 0x1e28000 - 0x1e29000: MDP 1 secure context
		 *
		 * 0x1e29000 - 0x1e2a000: RPM peripheral non-secure context
		 * 0x1e2a000 - 0x1e2b000: LPASS non-secure context
		 * 0x1e2b000 - 0x1e2c000: PRONTO PIL non-secure context
		 * 0x1e2c000 - 0x1e2d000: Q6 non-secure context
		 * 0x1e2d000 - 0x1e2e000: UNUSED / UNKNOWN non-secure? CONTEXT
		 * 0x1e2e000 - 0x1e2f000: UNUSED / UNKNOWN non-secure? CONTEXT
		 * 0x1e2f000 - 0x1e30000: ADSP I/O non-secure context
		 * 0x1e30000 - 0x1e31000: ADSP OpenDSP non-secure context
		 * 0x1e31000 - 0x1e32000: ADSP Shared non-secure context
		 * 0x1e32000 - 0x1e33000: LPASS stream non-secure context
		 * 0x1e33000 - 0x1e34000: CPP non-secure context
		 * 0x1e34000 - 0x1e35000: JPEG Encoder 0 non-secure context
		 * 0x1e35000 - 0x1e36000: VFE non-secure context
		 * 0x1e36000 - 0x1e37000: Venus non-secure context
		 * 0x1e37000 - 0x1e38000: MDP 0 non-secure context
		 * 0x1e38000 - 0x1e39000: PRONTO buffer non-secure context
		 * 0x1e39000 - 0x1e3a000: MSS NAV(?) non-secure context
		 * 0x1e3a000 - 0x1e3b000: IPA shared non-secure context
		 * 0x1e3b000 - 0x1e3c000: IPA WLAN non-secure context
		 * 0x1e3c000 - 0x1e3d000: IPA uC non-secure context
		 *
		 *  === config irqs ===
		 * global_cfg_S_irq:  <GIC_SPI 41 IRQ_TYPE_LEVEL_HIGH>
		 * global_cfg_NS_irq: <GIC_SPI 38 IRQ_TYPE_LEVEL_HIGH>
		 *
		 *  === Secure contexts IRQs ===
		 * ADSP ELF: 		254		ADSP sec pixel:		255
		 * ADSP sec bitstream:	53
		 *
		 * Venus sec firmware:	54		Venus sec non-pixel:	58
		 * Venus sec bitstream:	60		Venus sec pixel:	61
		 * Venus encoder:	76
		 *
		 * MDP 1:		77
		 *
		 *  === Non-secure contexts IRQs ===
		 * RPM Peripheral:	80		LPASS:			94
		 * PRONTO PIL:		101		Q6:			102
		 * ADSP I/O:		105		ADSP OpenDSP:		106
		 * ADSP Shared:		109		LPASS Stream:		110
		 * CPP:			111		JPEG Encoder 0:		112
		 * VFE:			113		Venus non-secure:	114
		 * MDP 0:		115		PRONTO Buffer:		116
		 *
		 * MSS NAV:		117
		 *
		 * IPA Shared:		118		IPA WLAN:		119
		 * IPA uC:		120
		 */

		apps_iommu: qcom,iommu@1e00000 {
			compatible = "qcom,msm-smmu-v2", "qcom,msm-mmu-500";
			#address-cells = <1>;
			#size-cells = <1>;
			//ranges;
			reg = <0x1e00000 0x40000>;
			reg-names = "iommu_base";
			interrupts = <GIC_SPI 41 IRQ_TYPE_LEVEL_HIGH>,
				     <GIC_SPI 38 IRQ_TYPE_LEVEL_HIGH>;
			interrupt-names = "global_cfg_NS_irq", "global_cfg_S_irq";
			label = "apps_iommu";
			qcom,qcom,use-aarch64-addressing;
			qcom,iommu-secure-id = <17>;
			clocks = <&gcc GCC_SMMU_CFG_CLK>,
				 <&gcc GCC_APSS_TCU_CLK>;
			clock-names = "iface_clk", "core_clk";
			qcom,cb-base-offset = <0x20000>;
			#iommu-cells = <1>;
			status = "ok";

			adsp_elf: iommu-ctx@1e20000 {
				compatible = "qcom,msm-smmu-v2-ctx";
				reg = <0x1e20000 0x1000>;
				qcom,secure-context;
				qcom,ctx-num = <1>;
				interrupts = <GIC_SPI 254 IRQ_TYPE_LEVEL_HIGH>;
				label = "adsp_elf";
			};

			adsp_sec_pixel: iommu-ctx@1e21000 {
				compatible = "qcom,msm-smmu-v2-ctx";
				reg = <0x1e21000 0x1000>;
				qcom,secure-context;
				qcom,ctx-num = <2>;
				interrupts = <GIC_SPI 255 IRQ_TYPE_LEVEL_HIGH>;
				label = "adsp_sec_pixel";
			};

			adsp_sec_bitstream: iommu-ctx@1e22000 {
				compatible = "qcom,msm-smmu-v2-ctx";
				reg = <0x1e22000 0x1000>;
				qcom,secure-context;
				qcom,ctx-num = <3>;
				interrupts = <GIC_SPI 53 IRQ_TYPE_LEVEL_HIGH>;
				label = "adsp_sec_bitstream";
			};

			venus_fw: iommu-ctx@1e23000 {
				compatible = "qcom,msm-smmu-v2-ctx";
				reg = <0x1e23000 0x1000>;
				qcom,secure-context;
				qcom,ctx-num = <4>;
				interrupts = <GIC_SPI 54 IRQ_TYPE_LEVEL_HIGH>;
				label = "venus_fw";
				qcom,report-error-on-fault;
			};

			venus_sec_non_pixel: iommu-ctx@1e24000 {
				compatible = "qcom,msm-smmu-v2-ctx";
				reg = <0x1e24000 0x1000>;
				qcom,secure-context;
				qcom,ctx-num = <5>;
				interrupts = <GIC_SPI 58 IRQ_TYPE_LEVEL_HIGH>;
				label = "venus_sec_non_pixel";
				qcom,report-error-on-fault;
			};

			venus_sec_bitstream: iommu-ctx@1e25000 {
				compatible = "qcom,msm-smmu-v2-ctx";
				reg = <0x1e25000 0x1000>;
				qcom,secure-context;
				qcom,ctx-num = <6>;
				interrupts = <GIC_SPI 60 IRQ_TYPE_LEVEL_HIGH>;
				label = "venus_sec_bitstream";
				qcom,report-error-on-fault;
			};

			venus_sec_pixel: iommu-ctx@1e26000 {
				compatible = "qcom,msm-smmu-v2-ctx";
				reg = <0x1e26000 0x1000>;
				qcom,secure-context;
				qcom,ctx-num = <7>;
				interrupts = <GIC_SPI 61 IRQ_TYPE_LEVEL_HIGH>;
				label = "venus_sec_pixel";
				qcom,report-error-on-fault;
			};

			venus_enc: iommu-ctx@1e27000 {
				compatible = "qcom,msm-smmu-v2-ctx";
				reg = <0x1e27000 0x1000>;
				qcom,secure-context;
				qcom,ctx-num = <8>;
				interrupts = <GIC_SPI 76 IRQ_TYPE_LEVEL_HIGH>;
				label = "venus_enc";
				qcom,report-error-on-fault;
			};

			mdp_1: iommu-ctx@1e28000 {
				compatible = "qcom,msm-smmu-v2-ctx";
				reg = <0x1e28000 0x1000>;
				qcom,secure-context;
				qcom,ctx-num = <9>;
				interrupts = <GIC_SPI 77 IRQ_TYPE_LEVEL_HIGH>;
				label = "mdp_1";
			};

			periph_rpm: iommu-ctx@1e29000 {
				compatible = "qcom,msm-smmu-v2-ctx";
				reg = <0x1e29000 0x1000>;
				interrupts = <GIC_SPI 80 IRQ_TYPE_LEVEL_HIGH>;
				qcom,ctx-num = <10>;
				label = "periph_rpm";
			};

			lpass: iommu-ctx@1e2a000 {
				compatible = "qcom,msm-smmu-v2-ctx";
				reg = <0x1e2a000 0x1000>;
				interrupts = <GIC_SPI 94 IRQ_TYPE_LEVEL_HIGH>;
				qcom,ctx-num = <11>;
				label = "lpass";
			};

			pronto_pil: iommu-ctx@1e2b000 {
				compatible = "qcom,msm-smmu-v2-ctx";
				reg = <0x1e2b000 0x1000>;
				interrupts = <GIC_SPI 101 IRQ_TYPE_LEVEL_HIGH>;
				qcom,ctx-num = <12>;
				label = "pronto_pil";
			};

			q6: iommu-ctx@1e2c000 {
				compatible = "qcom,msm-smmu-v2-ctx";
				reg = <0x1e2c000 0x1000>;
				interrupts = <GIC_SPI 102 IRQ_TYPE_LEVEL_HIGH>;
				qcom,ctx-num = <13>;
				label = "q6";
			};

			adsp_io: iommu-ctx@1e2f000 {
				compatible = "qcom,msm-smmu-v2-ctx";
				reg = <0x1e2f000 0x1000>;
				interrupts = <GIC_SPI 105 IRQ_TYPE_LEVEL_HIGH>;
				qcom,ctx-num = <14>;
				label = "adsp_io";
			};

			adsp_opendsp: iommu-ctx@1e30000 {
				compatible = "qcom,msm-smmu-v2-ctx";
				reg = <0x1e30000 0x1000>;
				interrupts = <GIC_SPI 106 IRQ_TYPE_LEVEL_HIGH>;
				qcom,ctx-num = <15>;
				label = "adsp_opendsp";
			};

			adsp_shared: iommu-ctx@1e31000 {
				compatible = "qcom,msm-smmu-v2-ctx";
				reg = <0x1e31000 0x1000>;
				interrupts = <GIC_SPI 109 IRQ_TYPE_LEVEL_HIGH>;
				qcom,ctx-num = <16>;
				label = "adsp_shared";
			};

			lpass_stream: iommu-ctx@1e32000 {
				compatible = "qcom,msm-smmu-v2-ctx";
				reg = <0x1e32000 0x1000>;
				interrupts = <GIC_SPI 110 IRQ_TYPE_LEVEL_HIGH>;
				qcom,ctx-num = <17>;
				label = "lpass_stream";
			};

			cpp: iommu-ctx@1e33000 {
				compatible = "qcom,msm-smmu-v2-ctx";
				reg = <0x1e33000 0x1000>;
				interrupts = <GIC_SPI 111 IRQ_TYPE_LEVEL_HIGH>;
				qcom,ctx-num = <18>;
				label = "cpp";
			};

			jpeg_enc0: iommu-ctx@1e34000 {
				compatible = "qcom,msm-smmu-v2-ctx";
				reg = <0x1e34000 0x1000>;
				interrupts = <GIC_SPI 112 IRQ_TYPE_LEVEL_HIGH>;
				qcom,ctx-num = <19>;
				label = "jpeg_enc0";
			};

			vfe: iommu-ctx@1e35000 {
				compatible = "qcom,msm-smmu-v2-ctx";
				reg = <0x1e35000 0x1000>;
				interrupts = <GIC_SPI 113 IRQ_TYPE_LEVEL_HIGH>;
				qcom,ctx-num = <20>;
				label = "vfe";
			};

			venus_ns: iommu-ctx@1e36000 {
				compatible = "qcom,msm-smmu-v2-ctx";
				reg = <0x1e36000 0x1000>;
				interrupts = <GIC_SPI 114 IRQ_TYPE_LEVEL_HIGH>;
				qcom,ctx-num = <21>;
				label = "venus_ns";
				qcom,report-error-on-fault;
			};

			mdp_0: iommu-ctx@1e37000 {
				compatible = "qcom,msm-smmu-v2-ctx";
				reg = <0x1e37000 0x1000>;
				interrupts = <GIC_SPI 115 IRQ_TYPE_LEVEL_HIGH>;
				qcom,ctx-num = <22>;
				label = "mdp_0";
			};

			pronto_buf: iommu-ctx@1e38000 {
				compatible = "qcom,msm-smmu-v2-ctx";
				reg = <0x1e38000 0x1000>;
				interrupts = <GIC_SPI 116 IRQ_TYPE_LEVEL_HIGH>;
				qcom,ctx-num = <23>;
				label = "pronto_buf";
			};

			mss_nav: iommu-ctx@1e39000 {
				compatible = "qcom,msm-smmu-v2-ctx";
				reg = <0x1e39000 0x1000>;
				interrupts = <GIC_SPI 117 IRQ_TYPE_LEVEL_HIGH>;
				qcom,ctx-num = <24>;
				label = "mss_nav";
			};

			ipa_shared: iommu-ctx@1e3a000 {
				compatible = "qcom,msm-smmu-v2-ctx";
				reg = <0x1e3a000 0x1000>;
				interrupts = <GIC_SPI 118 IRQ_TYPE_LEVEL_HIGH>;
				qcom,ctx-num = <25>;
				label = "ipa_shared";
			};

			ipa_wlan: iommu-ctx@1e3b000 {
				compatible = "qcom,msm-smmu-v2-ctx";
				reg = <0x1e3b000 0x1000>;
				interrupts = <GIC_SPI 119 IRQ_TYPE_LEVEL_HIGH>;
				qcom,ctx-num = <26>;
				label = "ipa_wlan";
			};

			ipa_uc: iommu-ctx@1e3c000 {
				compatible = "qcom,msm-smmu-v2-ctx";
				reg = <0x1e3c000 0x1000>;
				interrupts = <GIC_SPI 120 IRQ_TYPE_LEVEL_HIGH>;
				qcom,ctx-num = <27>;
				label = "ipa_uc";
			};
		};
#endif
		mdss: mdss@1a00000 {
			compatible = "qcom,mdss";
			reg = <0x1a00000 0x1000>,
			      <0x1ac8000 0x3000>;
			reg-names = "mdss_phys", "vbif_phys";

			vdd-supply = <&pm8950_l17>;
			power-domains = <&gcc MDSS_GDSC>;

			clocks = <&gcc GCC_MDSS_AHB_CLK>,
				 <&gcc GCC_MDSS_AXI_CLK>,
				 <&gcc GCC_MDSS_VSYNC_CLK>;
			clock-names = "iface",
				      "bus",
				      "vsync";

			interrupts = <GIC_SPI 72 IRQ_TYPE_LEVEL_HIGH>;

			interrupt-controller;
			#interrupt-cells = <1>;

			#address-cells = <1>;
			#size-cells = <1>;
			ranges;

			mdp: mdp@1a01000 {
				compatible = "qcom,mdp5";
				reg = <0x1a01000 0x89000>;
				reg-names = "mdp_phys";

				interrupt-parent = <&mdss>;
				interrupts = <0 IRQ_TYPE_LEVEL_HIGH>;

				/* TODO: Handle TBU and TBU_RT clocks */
				clocks = <&gcc GCC_MDSS_AHB_CLK>,
					 <&gcc GCC_MDSS_AXI_CLK>,
					 <&gcc GCC_MDSS_MDP_CLK>,
					 <&gcc GCC_MDSS_VSYNC_CLK>,
					 <&gcc GCC_MDP_TBU_CLK>,
					 <&gcc GCC_MDP_RT_TBU_CLK>;
				clock-names = "iface",
					      "bus",
					      "core",
					      "vsync",
					      "tbu",
					      "tbu_rt";

				iommus = <&apps_iommu 22>;

				ports {
					#address-cells = <1>;
					#size-cells = <0>;

					port@0 {
						reg = <0>;
						mdp5_intf1_out: endpoint {
							remote-endpoint = <&dsi0_in>;
						};
					};

					port@1 {
						reg = <1>;
						mdp5_intf2_out: endpoint {
							remote-endpoint = <&dsi1_in>;
						};
					};
				};
			};

			dsi0: dsi@1a94000 {
				compatible = "qcom,mdss-dsi-ctrl";
				reg = <0x1a94000 0x25c>;
				reg-names = "dsi_ctrl";
				#address-cells = <1>;
				#size-cells = <0>;

				interrupt-parent = <&mdss>;
				interrupts = <4 IRQ_TYPE_LEVEL_HIGH>;

				vdda-supply = <&pm8950_l1>;
				vddio-supply = <&pm8950_l6>;

				assigned-clocks =
					<&gcc GCC_MDSS_BYTE0_CLK_SRC>,
					<&gcc GCC_MDSS_PCLK0_CLK_SRC>;
				assigned-clock-parents = <&dsi_phy0 0>,
							 <&dsi_phy0 1>;

				clocks = <&gcc GCC_MDSS_MDP_CLK>,
					 <&gcc GCC_MDSS_AHB_CLK>,
					 <&gcc GCC_MDSS_AXI_CLK>,
					 <&gcc GCC_MDSS_BYTE0_CLK>,
					 <&gcc GCC_MDSS_PCLK0_CLK>,
					 <&gcc GCC_MDSS_ESC0_CLK>;
				clock-names = "mdp_core",
					      "iface",
					      "bus",
					      "byte",
					      "pixel",
					      "core";
				phys = <&dsi_phy0>;
				phy-names = "dsi-phy";

				qcom,mdss-mdp-transfer-time-us = <12000>;

				ports {
					#address-cells = <1>;
					#size-cells = <0>;

					port@0 {
						reg = <0>;
						dsi0_in: endpoint {
							remote-endpoint = <&mdp5_intf1_out>;
						};
					};

					port@1 {
						reg = <1>;
						dsi0_out: endpoint {
						};
					};
				};
			};

			dsi1: dsi@1a96000 {
				compatible = "qcom,mdss-dsi-ctrl";
				reg = <0x1a96000 0x300>;
				reg-names = "dsi_ctrl";
				#address-cells = <1>;
				#size-cells = <1>;

				interrupt-parent = <&mdss>;
				interrupts = <5 IRQ_TYPE_LEVEL_HIGH>;

				vdda-supply = <&pm8950_l1>;
				vddio-supply = <&pm8950_l6>;

				assigned-clocks =
					<&gcc GCC_MDSS_BYTE1_CLK_SRC>,
					<&gcc GCC_MDSS_PCLK1_CLK_SRC>;
				assigned-clock-parents = <&dsi_phy1 0>,
							 <&dsi_phy1 1>;

				clocks = <&gcc GCC_MDSS_MDP_CLK>,
					 <&gcc GCC_MDSS_AHB_CLK>,
					 <&gcc GCC_MDSS_AXI_CLK>,
					 <&gcc GCC_MDSS_BYTE1_CLK>,
					 <&gcc GCC_MDSS_PCLK1_CLK>,
					 <&gcc GCC_MDSS_ESC1_CLK>;
				clock-names = "mdp_core",
					      "iface",
					      "bus",
					      "byte",
					      "pixel",
					      "core";
				phys = <&dsi_phy0>;
				phy-names = "dsi-phy";

				status = "disabled";

				qcom,mdss-mdp-transfer-time-us = <12000>;

				ports {
					#address-cells = <1>;
					#size-cells = <0>;

					port@0 {
						reg = <0>;
						dsi1_in: endpoint {
							remote-endpoint = <&mdp5_intf2_out>;
						};
					};

					port@1 {
						reg = <1>;
						dsi1_out: endpoint {
						};
					};
				};
			};

			dsi_phy0: dsi-phy@1a94a00 {
				compatible = "qcom,dsi-phy-28nm-hpm-fam-b";
				reg = <0x1a94a00 0xd4>,
				      <0x1a94400 0x280>,
				      <0x1a94b80 0x30>;
				reg-names = "dsi_pll",
					    "dsi_phy",
					    "dsi_phy_regulator";

				#clock-cells = <1>;
				#phy-cells = <0>;

				vddio-supply = <&pm8950_l6>;

				clocks = <&gcc GCC_MDSS_AHB_CLK>,
					 <&xo_board>;
				clock-names = "iface", "ref";
			};

			dsi_phy1: dsi-phy@1a96a00 {
				compatible = "qcom,dsi-phy-28nm-hpm-fam-b";
				reg = <0x1a96a00 0xd4>,
				      <0x1a96400 0x280>,
				      <0x1a96b80 0x30>;
				reg-names = "dsi_pll",
					    "dsi_phy",
					    "dsi_phy_regulator";

				#clock-cells = <1>;
				#phy-cells = <0>;

				vddio-supply = <&pm8950_l6>;

				clocks = <&gcc GCC_MDSS_AHB_CLK>,
					 <&xo_board>;
				clock-names = "iface", "ref";
				status = "disabled";
			};
		};

		venus: video-codec@1d00000 {
			compatible = "qcom,msm8956-venus";
			reg = <0x01d00000 0xff000>;
			interrupts = <GIC_SPI 44 IRQ_TYPE_LEVEL_HIGH>;
			power-domains = <&gcc VENUS_CORE0_GDSC>;
			clocks = <&gcc GCC_VENUS0_VCODEC0_CLK>,
				 <&gcc GCC_VENUS0_CORE0_VCODEC0_CLK>,
				 <&gcc GCC_VENUS0_AHB_CLK>,
				 <&gcc GCC_VENUS0_AXI_CLK>;
			clock-names = "core", "core0", "iface", "bus";
			iommus = <&apps_iommu 21>;
			memory-region = <&venus_region>;
			status = "disabled";

			video-decoder {
				compatible = "venus-decoder";
			};

			video-encoder {
				compatible = "venus-encoder";
			};
		};

		camss: camss@1b00000 {
			compatible = "qcom,msm8956-camss";
			reg = <0x1b0ac00 0x200>,
				<0x1b00030 0x4>,
				<0x1b0b000 0x200>,
				<0x1b00038 0x4>,
				<0x1b08000 0x100>,
				<0x1b08400 0x100>,
				<0x1b08800 0x100>,
				<0x1b0a000 0x500>,
				<0x1b00020 0x10>,
				<0x1b10000 0x1000>,
				<0x1b14000 0x1000>;
			reg-names = "csiphy0",
				"csiphy0_clk_mux",
				"csiphy1",
				"csiphy1_clk_mux",
				"csid0",
				"csid1",
				"csid2",
				"ispif",
				"csi_clk_mux",
				"vfe0",
				"vfe1";
			interrupts = <GIC_SPI 78 IRQ_TYPE_EDGE_RISING>,
				<GIC_SPI 79 IRQ_TYPE_EDGE_RISING>,
				<GIC_SPI 51 IRQ_TYPE_EDGE_RISING>,
				<GIC_SPI 52 IRQ_TYPE_EDGE_RISING>,
				<GIC_SPI 153 IRQ_TYPE_EDGE_RISING>,
				<GIC_SPI 55 IRQ_TYPE_EDGE_RISING>,
				<GIC_SPI 57 IRQ_TYPE_EDGE_RISING>,
				<GIC_SPI 29 IRQ_TYPE_EDGE_RISING>;
			interrupt-names = "csiphy0",
				"csiphy1",
				"csid0",
				"csid1",
				"csid2",
				"ispif",
				"vfe0",
				"vfe1";
			power-domains = <&gcc VFE0_GDSC>,
					<&gcc VFE1_GDSC>;
			clocks = <&gcc GCC_CAMSS_TOP_AHB_CLK>,
				<&gcc GCC_CAMSS_ISPIF_AHB_CLK>,
				<&gcc GCC_CAMSS_CSI0PHYTIMER_CLK>,
				<&gcc GCC_CAMSS_CSI1PHYTIMER_CLK>,
				<&gcc GCC_CAMSS_CSI0_AHB_CLK>,
				<&gcc GCC_CAMSS_CSI0_CLK>,
				<&gcc GCC_CAMSS_CSI0PHY_CLK>,
				<&gcc GCC_CAMSS_CSI0PIX_CLK>,
				<&gcc GCC_CAMSS_CSI0RDI_CLK>,
				<&gcc GCC_CAMSS_CSI1_AHB_CLK>,
				<&gcc GCC_CAMSS_CSI1_CLK>,
				<&gcc GCC_CAMSS_CSI1PHY_CLK>,
				<&gcc GCC_CAMSS_CSI1PIX_CLK>,
				<&gcc GCC_CAMSS_CSI1RDI_CLK>,
				<&gcc GCC_CAMSS_CSI2_AHB_CLK>,
				<&gcc GCC_CAMSS_CSI2_CLK>,
				<&gcc GCC_CAMSS_CSI2PHY_CLK>,
				<&gcc GCC_CAMSS_CSI2PIX_CLK>,
				<&gcc GCC_CAMSS_CSI2RDI_CLK>,
				<&gcc GCC_CAMSS_AHB_CLK>,
				<&gcc GCC_CAMSS_VFE0_CLK>,
				<&gcc GCC_CAMSS_CSI_VFE0_CLK>,
				<&gcc GCC_CAMSS_VFE1_CLK>,
				<&gcc GCC_CAMSS_CSI_VFE1_CLK>,
				<&gcc GCC_CAMSS_VFE_AHB_CLK>,
				<&gcc GCC_CAMSS_VFE_AXI_CLK>;
			clock-names = "top_ahb",
				"ispif_ahb",
				"csiphy0_timer",
				"csiphy1_timer",
				"csi0_ahb",
				"csi0",
				"csi0_phy",
				"csi0_pix",
				"csi0_rdi",
				"csi1_ahb",
				"csi1",
				"csi1_phy",
				"csi1_pix",
				"csi1_rdi",
				"csi2_ahb",
				"csi2",
				"csi2_phy",
				"csi2_pix",
				"csi2_rdi",
				"ahb",
				"vfe0",
				"csi_vfe0",
				"vfe1",
				"csi_vfe1",
				"vfe_ahb",
				"vfe_axi";
			vdda-supply = <&pm8950_l6>;
			iommus = <&apps_iommu 20>;
			status = "disabled";
			ports {
				#address-cells = <1>;
				#size-cells = <0>;
			};
		};
	};

	hexagon@4080000 {
			compatible = "qcom,q6v5-pil";
			reg = <0x04080000 0x100>,
			      <0x04020000 0x040>;

			reg-names = "qdsp6", "rmb";

			interrupts-extended = <&intc 0 293 1>,
					      <&adsp_smp2p_in 0 0>,
					      <&adsp_smp2p_in 2 0>,
					      <&adsp_smp2p_in 1 0>,
					      <&adsp_smp2p_in 3 0>;
			interrupt-names = "wdog", "fatal", "ready",
					  "handover", "stop-ack";

/*
			clocks = <&rpmcc RPM_SMD_XO_CLK_SRC>,
				 <&gcc GCC_MSS_CFG_AHB_CLK>,
				 <&gcc GCC_MSS_Q6_BIMC_AXI_CLK>,
				 <&gcc GCC_BOOT_ROM_AHB_CLK>,
				 <&rpmcc RPM_SMD_QDSS_CLK>;
			clock-names = "xo", "iface_clk", "bus_clk", "mem_clk",
					"qdss_clk";
			qcom,proxy-clock-names = "xo", "qdss_clk";
			qcom,active-clock-names = "iface_clk", "bus_clk", "mem_clk";
*/
			clocks = <&gcc GCC_MSS_CFG_AHB_CLK>,
				 <&gcc GCC_MSS_Q6_BIMC_AXI_CLK>,
				 <&gcc GCC_BOOT_ROM_AHB_CLK>,
				 <&xo_board>;
			clock-names = "iface", "bus", "mem", "xo";

			qcom,smem-states = <&adsp_smp2p_out 0>;
			qcom,smem-state-names = "stop";

			resets = <&scm 0>;
			reset-names = "mss_restart";

			cx-supply = <&pm8950_s1>;
			mx-supply = <&pm8950_s2>; /* s2_level */
			pll-supply = <&pm8950_l7>;

			qcom,halt-regs = <&tcsr 0x18000 0x19000 0x1a000>;

			status = "disabled";

			mba {
				memory-region = <&lpass_region>;
			};

			mpss {
				memory-region = <&mpss_region>;
			};

			smd-edge {
				interrupts = <0 25 IRQ_TYPE_EDGE_RISING>;

				qcom,smd-edge = <0>;
				qcom,ipc = <&apcs 8 12>;
				qcom,remote-pid = <1>;

				label = "hexagon";
			};
		};
};

&thermal_zones {
	aoss0-thermal {
		polling-delay-passive = <250>;
		polling-delay = <1000>;

		thermal-sensors = <&tsens0 0>;
		trips {
			aoss0_alert: trip-point@0 {
				temperature = <105000>;
				hysteresis = <2000>;
				type = "hot";
			};
		};
	};

	mdm-core-thermal {
		polling-delay-passive = <250>;
		polling-delay = <1000>;

		thermal-sensors = <&tsens0 1>;
		trips {
			modem_alert: trip-point@0 {
				temperature = <95000>;
				hysteresis = <2000>;
				type = "hot";
			};
		};
	};

	qdsp-thermal {
		polling-delay-passive = <250>;
		polling-delay = <1000>;

		thermal-sensors = <&tsens0 2>;
		trips {
			qdsp_alert: trip-point@0 {
				temperature = <95000>;
				hysteresis = <2000>;
				type = "hot";
			};
		};
	};

	cam-isp-thermal {
		polling-delay-passive = <250>;
		polling-delay = <1000>;

		thermal-sensors = <&tsens0 3>;
		trips {
			cam_isp_alert: trip-point@0 {
				temperature = <95000>;
				hysteresis = <2000>;
				type = "hot";
			};
		};
	};

	apc1-cpu0-thermal {
		polling-delay-passive = <250>;
		polling-delay = <1000>;
		thermal-sensors = <&tsens0 4>;

		trips {
			cpu4_alert0: trip-point@0 {
				temperature = <95000>;
				hysteresis = <2000>;
				type = "hot";
			};
			cpu4_alert1: trip-point@1 {
				temperature = <105000>;
				hysteresis = <2000>;
				type = "passive";
			};
			cpu4_crit: trip-point@2 {
				temperature = <120000>;
				hysteresis = <2000>;
				type = "critical";
			};
		};
	};

	apc1-cpu1-thermal {
		polling-delay-passive = <250>;
		polling-delay = <1000>;
		thermal-sensors = <&tsens0 5>;

		trips {
			cpu5_alert0: trip-point@0 {
				temperature = <95000>;
				hysteresis = <2000>;
				type = "hot";
			};
			cpu5_alert1: trip-point@1 {
				temperature = <105000>;
				hysteresis = <2000>;
				type = "passive";
			};
			cpu5_crit: trip-point@2 {
				temperature = <120000>;
				hysteresis = <2000>;
				type = "critical";
			};
		};
	};

	apc1-cpu2-thermal {
		polling-delay-passive = <250>;
		polling-delay = <1000>;
		thermal-sensors = <&tsens0 6>;

		trips {
			cpu6_alert0: trip-point@0 {
				temperature = <95000>;
				hysteresis = <2000>;
				type = "hot";
			};
			cpu6_alert1: trip-point@1 {
				temperature = <105000>;
				hysteresis = <2000>;
				type = "passive";
			};
			cpu6_crit: trip-point@2 {
				temperature = <120000>;
				hysteresis = <2000>;
				type = "critical";
			};
		};
	};

	apc1-cpu3-thermal {
		polling-delay-passive = <250>;
		polling-delay = <1000>;
		thermal-sensors = <&tsens0 7>;

		trips {
			cpu7_alert0: trip-point@0 {
				temperature = <95000>;
				hysteresis = <2000>;
				type = "hot";
			};
			cpu7_alert1: trip-point@1 {
				temperature = <105000>;
				hysteresis = <2000>;
				type = "passive";
			};
			cpu7_crit: trip-point@2 {
				temperature = <120000>;
				hysteresis = <2000>;
				type = "critical";
			};
		};
	};

	apc1-l2-thermal {
		polling-delay-passive = <250>;
		polling-delay = <1000>;
		thermal-sensors = <&tsens0 8>;

		trips {
			l2_alert0: trip-point@0 {
				temperature = <95000>;
				hysteresis = <2000>;
				type = "hot";
			};
			l2_alert1: trip-point@1 {
				temperature = <105000>;
				hysteresis = <2000>;
				type = "passive";
			};
			l2_crit: trip-point@2 {
				temperature = <120000>;
				hysteresis = <2000>;
				type = "critical";
			};
		};
	};

	apc0-cpu0-thermal {
		polling-delay-passive = <250>;
		polling-delay = <1000>;
		thermal-sensors = <&tsens0 9>;

		trips {
			cpu0_alert0: trip-point@0 {
				temperature = <95000>;
				hysteresis = <2000>;
				type = "hot";
			};
			cpu0_alert1: trip-point@1 {
				temperature = <105000>;
				hysteresis = <2000>;
				type = "passive";
			};
			cpu0_crit: trip-point@2 {
				temperature = <120000>;
				hysteresis = <2000>;
				type = "critical";
			};
		};
	};
};

#include "msm8956-pins.dtsi"
